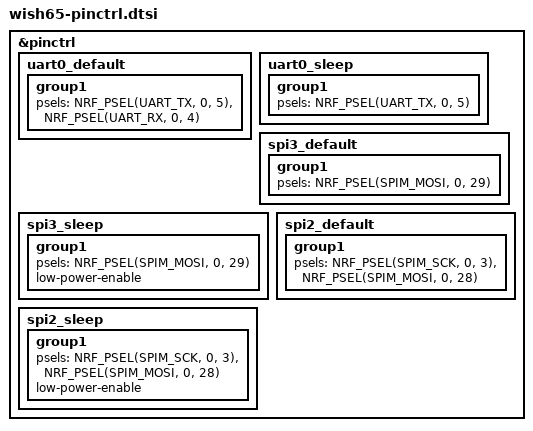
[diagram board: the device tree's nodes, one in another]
&pinctrl {
  /* 디버그 UART — 회로도 기준: TX = P0.05(AIN3), RX = P0.04(AIN2). 디버그 커넥터 H2(PH-01291). */
  uart0_default: uart0_default {
    group1 {
      psels = <NRF_PSEL(UART_TX, 0, 5)>, <NRF_PSEL(UART_RX, 0, 4)>;
    };
  };

  uart0_sleep: uart0_sleep {
    group1 {
      psels = <NRF_PSEL(UART_TX, 0, 5)>;
    };
  };

  /* ws2812(네오픽셀) — SPIM MOSI 만 쓴다. wish65 회로: P0.29 */
  spi3_default: spi3_default {
    group1 {
      psels = <NRF_PSEL(SPIM_MOSI, 0, 29)>;
    };
  };

  spi3_sleep: spi3_sleep {
    group1 {
      psels = <NRF_PSEL(SPIM_MOSI, 0, 29)>;
      low-power-enable;
    };
  };

  /* 74HC595 시프트레지스터 2개 직렬 — SCK P0.03, MOSI P0.28 (래치/CS 는 아래 cs-gpios) */
  spi2_default: spi2_default {
    group1 {
      psels = <NRF_PSEL(SPIM_SCK, 0, 3)>,
              <NRF_PSEL(SPIM_MOSI, 0, 28)>;
    };
  };

  spi2_sleep: spi2_sleep {
    group1 {
      psels = <NRF_PSEL(SPIM_SCK, 0, 3)>,
              <NRF_PSEL(SPIM_MOSI, 0, 28)>;
      low-power-enable;
    };
  };
};
